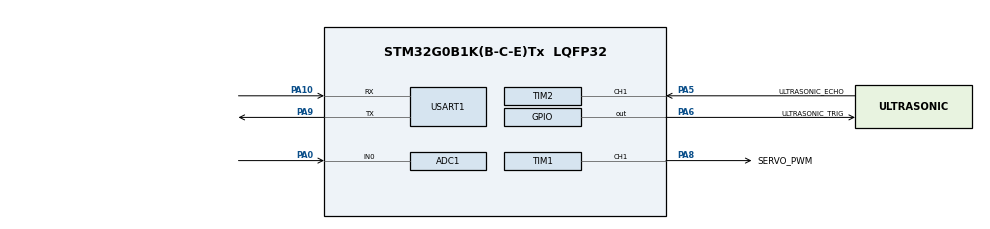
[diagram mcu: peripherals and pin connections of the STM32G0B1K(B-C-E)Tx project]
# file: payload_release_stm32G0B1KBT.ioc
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ADC1.Channel-0\#ChannelRegularConversion=ADC_CHANNEL_0
ADC1.NbrOfConversionFlag=1
ADC1.Rank-0\#ChannelRegularConversion=1
ADC1.SamplingTime-0\#ChannelRegularConversion=ADC_SAMPLINGTIME_COMMON_1
ADC1.SelectedChannel=ADC_CHANNEL_0
ADC1.master=1
Mcu.Family=STM32G0
Mcu.Name=STM32G0B1K(B-C-E)Tx
Mcu.Package=LQFP32
NVIC.TIM2_IRQn=true\:0\:0\:false\:false\:true\:true\:true\:true
NVIC.USART1_IRQn=true\:0\:0\:false\:false\:true\:true\:true\:true
PA0.Mode=IN0
PA0.Signal=ADC1_IN0
PA10.Mode=Asynchronous
PA10.Signal=USART1_RX
PA13.Mode=Serial_Wire
PA13.Signal=SYS_SWDIO
PA14-BOOT0.Mode=Serial_Wire
PA14-BOOT0.Signal=SYS_SWCLK
PA5.GPIO_Label=ULTRASONIC_ECHO
PA5.Signal=S_TIM2_CH1_ETR
PA6.GPIO_Label=ULTRASONIC_TRIG
PA6.Signal=GPIO_Output
PA8.GPIO_Label=SERVO_PWM
PA8.Signal=S_TIM1_CH1
PA9.Mode=Asynchronous
PA9.Signal=USART1_TX
ProjectManager.HeapSize=0x200
ProjectManager.StackSize=0x1000
ProjectManager.TargetToolchain=CMake
RCC.ADCFreq_Value=64000000
RCC.AHBFreq_Value=64000000
RCC.CortexFreq_Value=64000000
RCC.EXTERNAL_CLOCK_VALUE=48000
RCC.HCLKFreq_Value=64000000
RCC.HSE_VALUE=8000000
RCC.HSI48_VALUE=48000000
RCC.HSI_VALUE=16000000
RCC.LSE_VALUE=32768
RCC.SYSCLKFreq_VALUE=64000000
RCC.SYSCLKSource=RCC_SYSCLKSOURCE_PLLCLK
RCC.USBFreq_Value=48000000
RCC.VCOOutputFreq_Value=128000000
SH.S_TIM1_CH1.0=TIM1_CH1,PWM Generation1 CH1
SH.S_TIM2_CH1_ETR.0=TIM2_CH1,Input_Capture1_from_TI1
TIM1.AutoReloadPreload=TIM_AUTORELOAD_PRELOAD_ENABLE
TIM1.Channel-PWM\ Generation1\ CH1=TIM_CHANNEL_1
TIM1.CounterMode=TIM_COUNTERMODE_UP
TIM1.Period=19999
TIM1.Prescaler=63
TIM1.Pulse-PWM\ Generation1\ CH1=1500
TIM2.Channel-Input_Capture1_from_TI1=TIM_CHANNEL_1
TIM2.Prescaler=63
USART1.VirtualMode-Asynchronous=VM_ASYNC
VP_SYS_VS_DBSignals.Mode=DisableDeadBatterySignals
VP_TIM1_VS_ClockSourceINT.Mode=Internal
VP_TIM1_VS_ClockSourceITR.Mode=TriggerSource_ITR0
VP_TIM2_VS_ClockSourceINT.Mode=Internal
board=custom

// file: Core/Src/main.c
/* USER CODE BEGIN Header */
/**
  ******************************************************************************
  * @file           : main.c
  * @brief          : Main program body
  ******************************************************************************
  * @attention
  *
  * Copyright (c) 2026 STMicroelectronics.
  * All rights reserved.
  *
  * This software is licensed under terms that can be found in the LICENSE file
  * in the root directory of this software component.
  * If no LICENSE file comes with this software, it is provided AS-IS.
  *
  ******************************************************************************
  */
/* USER CODE END Header */
#include "main.h"

/* USER CODE BEGIN Includes */
#include "state_machine.h"
/* USER CODE END Includes */

TIM_HandleTypeDef htim2;

void SystemClock_Config(void);
static void MX_GPIO_Init(void);
static void MX_TIM1_Init(void);
static void MX_USART1_UART_Init(void);
static void MX_ADC1_Init(void);
static void MX_TIM2_Init(void);

int main(void)
{

  /* MCU Configuration--------------------------------------------------------*/

  /* Reset of all peripherals, Initializes the Flash interface and the Systick. */
  HAL_Init();

  /* Configure the system clock */
  SystemClock_Config();

  /* Initialize all configured peripherals */
  MX_GPIO_Init();
  MX_TIM1_Init();
  MX_USART1_UART_Init();
  MX_ADC1_Init();
  MX_TIM2_Init();

  /* Infinite loop */
  /* USER CODE BEGIN WHILE */
  state_machine_loop();
  /* USER CODE END 3 */
}

void SystemClock_Config(void)
{
  LL_FLASH_SetLatency(LL_FLASH_LATENCY_2);
  while(LL_FLASH_GetLatency() != LL_FLASH_LATENCY_2)
  {
  }

  /* HSI configuration and activation */
  LL_RCC_HSI_Enable();
  while(LL_RCC_HSI_IsReady() != 1)
  {
  }

  /* Main PLL configuration and activation */
  LL_RCC_PLL_ConfigDomain_SYS(LL_RCC_PLLSOURCE_HSI, LL_RCC_PLLM_DIV_1, 8, LL_RCC_PLLR_DIV_2);
  LL_RCC_PLL_Enable();
  LL_RCC_PLL_EnableDomain_SYS();
  while(LL_RCC_PLL_IsReady() != 1)
  {
  }

  /* Set AHB prescaler*/
  LL_RCC_SetAHBPrescaler(LL_RCC_SYSCLK_DIV_1);

  /* Sysclk activation on the main PLL */
  LL_RCC_SetSysClkSource(LL_RCC_SYS_CLKSOURCE_PLL);
  while(LL_RCC_GetSysClkSource() != LL_RCC_SYS_CLKSOURCE_STATUS_PLL)
  {
  }

  /* Set APB1 prescaler*/
  LL_RCC_SetAPB1Prescaler(LL_RCC_APB1_DIV_1);
  /* Update CMSIS variable (which can be updated also through SystemCoreClockUpdate function) */
  LL_SetSystemCoreClock(64000000);

   /* Update the time base */
  if (HAL_InitTick (TICK_INT_PRIORITY) != HAL_OK)
  {
    Error_Handler();
  }
}

static void MX_ADC1_Init(void)
{

  LL_ADC_InitTypeDef ADC_InitStruct = {0};
  LL_ADC_REG_InitTypeDef ADC_REG_InitStruct = {0};

  LL_GPIO_InitTypeDef GPIO_InitStruct = {0};

  /* Peripheral clock enable */
  LL_APB2_GRP1_EnableClock(LL_APB2_GRP1_PERIPH_ADC);

  LL_IOP_GRP1_EnableClock(LL_IOP_GRP1_PERIPH_GPIOA);
  /**ADC1 GPIO Configuration
  PA0   ------> ADC1_IN0
  */
  GPIO_InitStruct.Pin = LL_GPIO_PIN_0;
  GPIO_InitStruct.Mode = LL_GPIO_MODE_ANALOG;
  GPIO_InitStruct.Pull = LL_GPIO_PULL_NO;
  LL_GPIO_Init(GPIOA, &GPIO_InitStruct);

  /** Configure the global features of the ADC (Clock, Resolution, Data Alignment and number of conversion)
  */

   #define ADC_CHANNEL_CONF_RDY_TIMEOUT_MS ( 1U)
   #if (USE_TIMEOUT == 1)
   uint32_t Timeout ; /* Variable used for Timeout management */
   #endif /* USE_TIMEOUT */

  ADC_InitStruct.Clock = LL_ADC_CLOCK_SYNC_PCLK_DIV2;
  ADC_InitStruct.Resolution = LL_ADC_RESOLUTION_12B;
  ADC_InitStruct.DataAlignment = LL_ADC_DATA_ALIGN_RIGHT;
  ADC_InitStruct.LowPowerMode = LL_ADC_LP_MODE_NONE;
  LL_ADC_Init(ADC1, &ADC_InitStruct);
  LL_ADC_REG_SetSequencerConfigurable(ADC1, LL_ADC_REG_SEQ_CONFIGURABLE);

   /* Poll for ADC channel configuration ready */
   #if (USE_TIMEOUT == 1)
   Timeout = ADC_CHANNEL_CONF_RDY_TIMEOUT_MS;
   #endif /* USE_TIMEOUT */
   while (LL_ADC_IsActiveFlag_CCRDY(ADC1) == 0)
     {
   #if (USE_TIMEOUT == 1)
   /* Check Systick counter flag to decrement the time-out value */
   if (LL_SYSTICK_IsActiveCounterFlag())
     {
   if(Timeout-- == 0)
         {
   Error_Handler();
         }
     }
   #endif /* USE_TIMEOUT */
     }
   /* Clear flag ADC channel configuration ready */
   LL_ADC_ClearFlag_CCRDY(ADC1);
  ADC_REG_InitStruct.TriggerSource = LL_ADC_REG_TRIG_SOFTWARE;
  ADC_REG_InitStruct.SequencerLength = LL_ADC_REG_SEQ_SCAN_DISABLE;
  ADC_REG_InitStruct.SequencerDiscont = LL_ADC_REG_SEQ_DISCONT_DISABLE;
  ADC_REG_InitStruct.ContinuousMode = LL_ADC_REG_CONV_SINGLE;
  ADC_REG_InitStruct.DMATransfer = LL_ADC_REG_DMA_TRANSFER_NONE;
  ADC_REG_InitStruct.Overrun = LL_ADC_REG_OVR_DATA_PRESERVED;
  LL_ADC_REG_Init(ADC1, &ADC_REG_InitStruct);
  LL_ADC_SetOverSamplingScope(ADC1, LL_ADC_OVS_DISABLE);
  LL_ADC_SetTriggerFrequencyMode(ADC1, LL_ADC_CLOCK_FREQ_MODE_HIGH);
  LL_ADC_SetSamplingTimeCommonChannels(ADC1, LL_ADC_SAMPLINGTIME_COMMON_1, LL_ADC_SAMPLINGTIME_1CYCLE_5);
  LL_ADC_SetSamplingTimeCommonChannels(ADC1, LL_ADC_SAMPLINGTIME_COMMON_2, LL_ADC_SAMPLINGTIME_1CYCLE_5);
  LL_ADC_DisableIT_EOC(ADC1);
  LL_ADC_DisableIT_EOS(ADC1);

   /* Enable ADC internal voltage regulator */
   LL_ADC_EnableInternalRegulator(ADC1);
   /* Delay for ADC internal voltage regulator stabilization. */
   /* Compute number of CPU cycles to wait for, from delay in us. */
   /* Note: Variable divided by 2 to compensate partially */
   /* CPU processing cycles (depends on compilation optimization). */
   /* Note: If system core clock frequency is below 200kHz, wait time */
   /* is only a few CPU processing cycles. */
   __IO uint32_t wait_loop_index;
   wait_loop_index = ((LL_ADC_DELAY_INTERNAL_REGUL_STAB_US * (SystemCoreClock / (100000 * 2))) / 10);
   while(wait_loop_index != 0)
     {
   wait_loop_index--;
     }

  /** Configure Regular Channel
  */
  LL_ADC_REG_SetSequencerRanks(ADC1, LL_ADC_REG_RANK_1, LL_ADC_CHANNEL_0);
  LL_ADC_SetChannelSamplingTime(ADC1, LL_ADC_CHANNEL_0, LL_ADC_SAMPLINGTIME_COMMON_1);

}

static void MX_TIM1_Init(void)
{

  LL_TIM_InitTypeDef TIM_InitStruct = {0};
  LL_TIM_OC_InitTypeDef TIM_OC_InitStruct = {0};
  LL_TIM_BDTR_InitTypeDef TIM_BDTRInitStruct = {0};

  LL_GPIO_InitTypeDef GPIO_InitStruct = {0};

  LL_RCC_SetTIMClockSource(LL_RCC_TIM1_CLKSOURCE_PCLK1);

  /* Peripheral clock enable */
  LL_APB2_GRP1_EnableClock(LL_APB2_GRP1_PERIPH_TIM1);

  TIM_InitStruct.Prescaler = 63;
  TIM_InitStruct.CounterMode = LL_TIM_COUNTERMODE_UP;
  TIM_InitStruct.Autoreload = 19999;
  TIM_InitStruct.ClockDivision = LL_TIM_CLOCKDIVISION_DIV1;
  TIM_InitStruct.RepetitionCounter = 0;
  LL_TIM_Init(TIM1, &TIM_InitStruct);
  LL_TIM_EnableARRPreload(TIM1);
  LL_TIM_SetClockSource(TIM1, LL_TIM_CLOCKSOURCE_INTERNAL);
  LL_TIM_OC_EnablePreload(TIM1, LL_TIM_CHANNEL_CH1);
  TIM_OC_InitStruct.OCMode = LL_TIM_OCMODE_PWM1;
  TIM_OC_InitStruct.OCState = LL_TIM_OCSTATE_DISABLE;
  TIM_OC_InitStruct.OCNState = LL_TIM_OCSTATE_DISABLE;
  TIM_OC_InitStruct.CompareValue = 1500;
  TIM_OC_InitStruct.OCPolarity = LL_TIM_OCPOLARITY_HIGH;
  TIM_OC_InitStruct.OCNPolarity = LL_TIM_OCPOLARITY_HIGH;
  TIM_OC_InitStruct.OCIdleState = LL_TIM_OCIDLESTATE_LOW;
  TIM_OC_InitStruct.OCNIdleState = LL_TIM_OCIDLESTATE_LOW;
  LL_TIM_OC_Init(TIM1, LL_TIM_CHANNEL_CH1, &TIM_OC_InitStruct);
  LL_TIM_OC_DisableFast(TIM1, LL_TIM_CHANNEL_CH1);
  LL_TIM_SetTriggerInput(TIM1, LL_TIM_TS_ITR0);
  LL_TIM_SetSlaveMode(TIM1, LL_TIM_SLAVEMODE_DISABLED);
  LL_TIM_DisableIT_TRIG(TIM1);
  LL_TIM_DisableDMAReq_TRIG(TIM1);
  LL_TIM_SetTriggerOutput(TIM1, LL_TIM_TRGO_RESET);
  LL_TIM_SetTriggerOutput2(TIM1, LL_TIM_TRGO2_RESET);
  LL_TIM_DisableMasterSlaveMode(TIM1);
  TIM_BDTRInitStruct.OSSRState = LL_TIM_OSSR_DISABLE;
  TIM_BDTRInitStruct.OSSIState = LL_TIM_OSSI_DISABLE;
  TIM_BDTRInitStruct.LockLevel = LL_TIM_LOCKLEVEL_OFF;
  TIM_BDTRInitStruct.DeadTime = 0;
  TIM_BDTRInitStruct.BreakState = LL_TIM_BREAK_DISABLE;
  TIM_BDTRInitStruct.BreakPolarity = LL_TIM_BREAK_POLARITY_HIGH;
  TIM_BDTRInitStruct.BreakFilter = LL_TIM_BREAK_FILTER_FDIV1;
  TIM_BDTRInitStruct.BreakAFMode = LL_TIM_BREAK_AFMODE_INPUT;
  TIM_BDTRInitStruct.Break2State = LL_TIM_BREAK2_DISABLE;
  TIM_BDTRInitStruct.Break2Polarity = LL_TIM_BREAK2_POLARITY_HIGH;
  TIM_BDTRInitStruct.Break2Filter = LL_TIM_BREAK2_FILTER_FDIV1;
  TIM_BDTRInitStruct.Break2AFMode = LL_TIM_BREAK_AFMODE_INPUT;
  TIM_BDTRInitStruct.AutomaticOutput = LL_TIM_AUTOMATICOUTPUT_DISABLE;
  LL_TIM_BDTR_Init(TIM1, &TIM_BDTRInitStruct);
  LL_IOP_GRP1_EnableClock(LL_IOP_GRP1_PERIPH_GPIOA);
  /**TIM1 GPIO Configuration
  PA8   ------> TIM1_CH1
  */
  GPIO_InitStruct.Pin = SERVO_PWM_Pin;
  GPIO_InitStruct.Mode = LL_GPIO_MODE_ALTERNATE;
  GPIO_InitStruct.Speed = LL_GPIO_SPEED_FREQ_LOW;
  GPIO_InitStruct.OutputType = LL_GPIO_OUTPUT_PUSHPULL;
  GPIO_InitStruct.Pull = LL_GPIO_PULL_NO;
  GPIO_InitStruct.Alternate = LL_GPIO_AF_2;
  LL_GPIO_Init(SERVO_PWM_GPIO_Port, &GPIO_InitStruct);

}

static void MX_TIM2_Init(void)
{

  TIM_ClockConfigTypeDef sClockSourceConfig = {0};
  TIM_MasterConfigTypeDef sMasterConfig = {0};
  TIM_IC_InitTypeDef sConfigIC = {0};

  htim2.Instance = TIM2;
  htim2.Init.Prescaler = 63;
  htim2.Init.CounterMode = TIM_COUNTERMODE_UP;
  htim2.Init.Period = 4294967295;
  htim2.Init.ClockDivision = TIM_CLOCKDIVISION_DIV1;
  htim2.Init.AutoReloadPreload = TIM_AUTORELOAD_PRELOAD_DISABLE;
  if (HAL_TIM_Base_Init(&htim2) != HAL_OK)
  {
    Error_Handler();
  }
  sClockSourceConfig.ClockSource = TIM_CLOCKSOURCE_INTERNAL;
  if (HAL_TIM_ConfigClockSource(&htim2, &sClockSourceConfig) != HAL_OK)
  {
    Error_Handler();
  }
  if (HAL_TIM_IC_Init(&htim2) != HAL_OK)
  {
    Error_Handler();
  }
  sMasterConfig.MasterOutputTrigger = TIM_TRGO_RESET;
  sMasterConfig.MasterSlaveMode = TIM_MASTERSLAVEMODE_DISABLE;
  if (HAL_TIMEx_MasterConfigSynchronization(&htim2, &sMasterConfig) != HAL_OK)
  {
    Error_Handler();
  }
  sConfigIC.ICPolarity = TIM_INPUTCHANNELPOLARITY_RISING;
  sConfigIC.ICSelection = TIM_ICSELECTION_DIRECTTI;
  sConfigIC.ICPrescaler = TIM_ICPSC_DIV1;
  sConfigIC.ICFilter = 0;
  if (HAL_TIM_IC_ConfigChannel(&htim2, &sConfigIC, TIM_CHANNEL_1) != HAL_OK)
  {
    Error_Handler();
  }

}

static void MX_USART1_UART_Init(void)
{

  LL_USART_InitTypeDef USART_InitStruct = {0};

  LL_GPIO_InitTypeDef GPIO_InitStruct = {0};

  LL_RCC_SetUSARTClockSource(LL_RCC_USART1_CLKSOURCE_PCLK1);

  /* Peripheral clock enable */
  LL_APB2_GRP1_EnableClock(LL_APB2_GRP1_PERIPH_USART1);

  LL_IOP_GRP1_EnableClock(LL_IOP_GRP1_PERIPH_GPIOA);
  /**USART1 GPIO Configuration
  PA9   ------> USART1_TX
  PA10   ------> USART1_RX
  */
  GPIO_InitStruct.Pin = LL_GPIO_PIN_9;
  GPIO_InitStruct.Mode = LL_GPIO_MODE_ALTERNATE;
  GPIO_InitStruct.Speed = LL_GPIO_SPEED_FREQ_LOW;
  GPIO_InitStruct.OutputType = LL_GPIO_OUTPUT_PUSHPULL;
  GPIO_InitStruct.Pull = LL_GPIO_PULL_NO;
  GPIO_InitStruct.Alternate = LL_GPIO_AF_1;
  LL_GPIO_Init(GPIOA, &GPIO_InitStruct);

  GPIO_InitStruct.Pin = LL_GPIO_PIN_10;
  GPIO_InitStruct.Mode = LL_GPIO_MODE_ALTERNATE;
  GPIO_InitStruct.Speed = LL_GPIO_SPEED_FREQ_LOW;
  GPIO_InitStruct.OutputType = LL_GPIO_OUTPUT_PUSHPULL;
  GPIO_InitStruct.Pull = LL_GPIO_PULL_NO;
  GPIO_InitStruct.Alternate = LL_GPIO_AF_1;
  LL_GPIO_Init(GPIOA, &GPIO_InitStruct);

  /* USART1 interrupt Init */
  NVIC_SetPriority(USART1_IRQn, 0);
  NVIC_EnableIRQ(USART1_IRQn);

  USART_InitStruct.PrescalerValue = LL_USART_PRESCALER_DIV1;
  USART_InitStruct.BaudRate = 115200;
  USART_InitStruct.DataWidth = LL_USART_DATAWIDTH_8B;
  USART_InitStruct.StopBits = LL_USART_STOPBITS_1;
  USART_InitStruct.Parity = LL_USART_PARITY_NONE;
  USART_InitStruct.TransferDirection = LL_USART_DIRECTION_TX_RX;
  USART_InitStruct.HardwareFlowControl = LL_USART_HWCONTROL_NONE;
  USART_InitStruct.OverSampling = LL_USART_OVERSAMPLING_16;
  LL_USART_Init(USART1, &USART_InitStruct);
  LL_USART_SetTXFIFOThreshold(USART1, LL_USART_FIFOTHRESHOLD_1_8);
  LL_USART_SetRXFIFOThreshold(USART1, LL_USART_FIFOTHRESHOLD_1_8);
  LL_USART_DisableFIFO(USART1);
  LL_USART_ConfigAsyncMode(USART1);

  LL_USART_Enable(USART1);

  /* Polling USART1 initialisation */
  while((!(LL_USART_IsActiveFlag_TEACK(USART1))) || (!(LL_USART_IsActiveFlag_REACK(USART1))))
  {
  }

}

static void MX_GPIO_Init(void)
{
  LL_GPIO_InitTypeDef GPIO_InitStruct = {0};

  /* GPIO Ports Clock Enable */
  LL_IOP_GRP1_EnableClock(LL_IOP_GRP1_PERIPH_GPIOA);

  /**/
  LL_GPIO_ResetOutputPin(ULTRASONIC_TRIG_GPIO_Port, ULTRASONIC_TRIG_Pin);

  /**/
  GPIO_InitStruct.Pin = ULTRASONIC_TRIG_Pin;
  GPIO_InitStruct.Mode = LL_GPIO_MODE_OUTPUT;
  GPIO_InitStruct.Speed = LL_GPIO_SPEED_FREQ_LOW;
  GPIO_InitStruct.OutputType = LL_GPIO_OUTPUT_PUSHPULL;
  GPIO_InitStruct.Pull = LL_GPIO_PULL_NO;
  LL_GPIO_Init(ULTRASONIC_TRIG_GPIO_Port, &GPIO_InitStruct);

}

void Error_Handler(void)
{
  __disable_irq();
  while (1)
  {
  }
}
